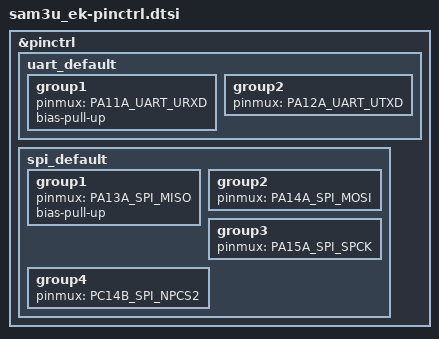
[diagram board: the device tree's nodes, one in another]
/*
 * Copyright (c) 2023 Chen Xingyu <hi@xingrz.me>
 * SPDX-License-Identifier: Apache-2.0
 */

#include <dt-bindings/pinctrl/sam3uXe-pinctrl.h>

&pinctrl {
	uart_default: uart_default {
		group1 {
			pinmux = <PA11A_UART_URXD>;
			bias-pull-up;
		};
		group2 {
			pinmux = <PA12A_UART_UTXD>;
		};
	};

	spi_default: spi_default {
		group1 {
			pinmux = <PA13A_SPI_MISO>;
			bias-pull-up;
		};
		group2 {
			pinmux = <PA14A_SPI_MOSI>;
		};
		group3 {
			pinmux = <PA15A_SPI_SPCK>;
		};
		group4 {
			pinmux = <PC14B_SPI_NPCS2>;
		};
	};
};
